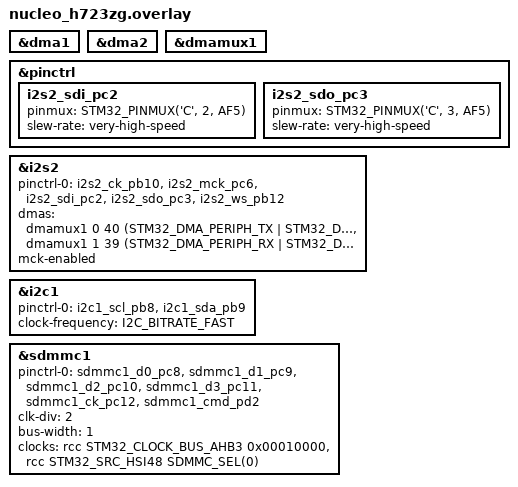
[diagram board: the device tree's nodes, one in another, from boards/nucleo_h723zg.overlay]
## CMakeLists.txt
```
# SPDX-License-Identifier: Apache-2.0

cmake_minimum_required(VERSION 3.20.0)

# Locate Zephyr and Project sources
find_package(Zephyr REQUIRED HINTS $ENV{ZEPHYR_BASE})

project(NucleoI2S)
FILE(GLOB app_sources src/*.c)
target_sources(app PRIVATE ${app_sources})
```

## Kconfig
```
menu "Zephyr"
source "Kconfig.zephyr"
endmenu

config DT_DEFINED_NOCACHE
	  bool "Enable this if nocache regions are defined in devicetree"

config DT_DEFINED_NOCACHE_NAME
	  string "Name of the nocache region defined in devicetree (capitals)"
```

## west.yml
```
# Copyright (c) 2021 Nordic Semiconductor ASA
# SPDX-License-Identifier: Apache-2.0

manifest:
  remotes:
    - name: zephyrproject-rtos-frf
      url-base: https://gitlab.firstrf.com/embedded/zephyr-demo/
    - name: zephyrproject-rtos
      url-base: https://github.com/zephyrproject-rtos

  projects:
    - name: zephyr
      remote: zephyrproject-rtos-frf
      revision: v3.6.0_frf-fixes
      import:
        # path-prefix: dep
        # By using name-allowlist we can clone only the modules that are
        # strictly needed by the application.
        name-allowlist:
          - cmsis      # required by the ARM port
          - hal_stm32  # required by stm32
          - mbedtls    # required for networking
          - littlefs   # required for settings storage
    - name: mcuboot
      remote: zephyrproject-rtos
      revision: a4eda30f5b0cfd0cf15512be9dcd559239dbfc91
      path: bootloader/mcuboot
    - name: net-tools
      remote: zephyrproject-rtos
      revision: 3a677d355cc7f73e444801a6280d0ccec80a1957
      path: tools/net-tools
    - name: zcbor
      remote: zephyrproject-rtos
      revision: d3093b5684f62268c7f27f8a5079f166772619de
      path: modules/lib/zcbor
```

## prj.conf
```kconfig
# Shell and loggings
CONFIG_SHELL=y
CONFIG_SHELL_HISTORY=y
CONFIG_SHELL_CMD_BUFF_SIZE=128
CONFIG_SHELL_STACK_SIZE=2048
CONFIG_LOG=y
CONFIG_PRINTK=y
CONFIG_MAIN_STACK_SIZE=10000

# I2S
CONFIG_I2S=y
CONFIG_I2S_STM32=y
CONFIG_HEAP_MEM_POOL_SIZE=81920

# I2C
CONFIG_I2C=y

# GPIO
CONFIG_GPIO=y
CONFIG_PINCTRL=y

# DMA
CONFIG_DMA=y

# SDMMC
CONFIG_FILE_SYSTEM=y
CONFIG_DISK_ACCESS=y
CONFIG_DISK_DRIVER_SDMMC=y
CONFIG_FAT_FILESYSTEM_ELM=y
CONFIG_SDMMC_STM32=y
CONFIG_SDMMC_STM32_CLOCK_CHECK=n
```

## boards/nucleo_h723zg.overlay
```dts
// this file overwrites zephyr/boards/st/nucleo_h723zg
// see that folder for complete board example

&dma1 {
    status = "okay";
};
&dma2 {
    status = "okay";
};
&dmamux1 {
    status = "okay";
};

&pinctrl {
    /omit-if-no-ref/ i2s2_sdi_pc2: i2s2_sdi_pc2 {
        pinmux = <STM32_PINMUX('C', 2, AF5)>;
        slew-rate = "very-high-speed";
    };

    /omit-if-no-ref/ i2s2_sdo_pc3: i2s2_sdo_pc3 {
        pinmux = <STM32_PINMUX('C', 3, AF5)>;
        slew-rate = "very-high-speed";
    };
};

&i2s2 {
    status = "okay";
    pinctrl-0 = <&i2s2_ck_pb10 &i2s2_mck_pc6 &i2s2_sdi_pc2 &i2s2_sdo_pc3 &i2s2_ws_pb12>;
    pinctrl-names = "default";
    dmas = <&dmamux1 0 40 (STM32_DMA_PERIPH_TX | STM32_DMA_PRIORITY_HIGH)
    &dmamux1 1 39 (STM32_DMA_PERIPH_RX | STM32_DMA_PRIORITY_HIGH)>;
    dma-names = "tx", "rx";
    mck-enabled;
};

&i2c1 {
    pinctrl-0 = <&i2c1_scl_pb8 &i2c1_sda_pb9>;
    pinctrl-names = "default";
    status = "okay";
    clock-frequency = <I2C_BITRATE_FAST>;
};

&sdmmc1 {
    status = "okay";
    pinctrl-0 = <
        &sdmmc1_d0_pc8
        &sdmmc1_d1_pc9
        &sdmmc1_d2_pc10
        &sdmmc1_d3_pc11
        &sdmmc1_ck_pc12
        &sdmmc1_cmd_pd2>;
    clk-div = <2>;
    bus-width = <1>;
    pinctrl-names = "default";
    clocks = <&rcc STM32_CLOCK_BUS_AHB3 0x00010000>,
        <&rcc STM32_SRC_HSI48 SDMMC_SEL(0)>;
};
```

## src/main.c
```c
#include <zephyr/kernel.h>
#include <zephyr/sys/printk.h>
#include <zephyr/drivers/i2s.h>
#include <zephyr/shell/shell.h>
#include <zephyr/drivers/i2c.h>
#include <math.h>
#include <string.h>
#include "wav_reader.h"

/* ----- definitions ----- */
#ifndef M_PI
#define M_PI 3.14159265358979323846
#endif

#define AIC3120_I2C_ADDR                                                                           \
	0x18 // Replace with your actual I2C address
	     //
#define SAMPLE_FREQUENCY   44100
#define SINE_FREQ          440   // Frequency of the sine wave (440 Hz, A4)
#define AMPLITUDE          32767 // Amplitude for 16-bit audio (max value)
#define SAMPLE_BIT_WIDTH   (16U)
#define BYTES_PER_SAMPLE   sizeof(int16_t)
#define NUMBER_OF_CHANNELS (2U)

/* Such block length provides an echo with the delay of 100 ms. */
#define SAMPLES_PER_BLOCK ((SAMPLE_FREQUENCY / 40) * NUMBER_OF_CHANNELS)
#define INITIAL_BLOCKS    2
#define TIMEOUT           (2000U)

#define BLOCK_SIZE  (BYTES_PER_SAMPLE * SAMPLES_PER_BLOCK)
#define BLOCK_COUNT (INITIAL_BLOCKS + 25)
K_MEM_SLAB_DEFINE_STATIC(mem_slab, BLOCK_SIZE, BLOCK_COUNT, 4);

/* ----- private static variables ----- */
static const struct device *dev_i2s;
static struct i2s_config i2s_cfg;
static bool stream_started = false;

static K_THREAD_STACK_DEFINE(tone_thread_stack, 4096); // Adjust stack size as needed
static struct k_thread tone_thread_data;

/* ----- private function declarations ----- */
void aic3120Init();
static bool configure_tx_streams(const struct device *dev_i2s, struct i2s_config *config);
static bool trigger_command(const struct device *dev_i2s, enum i2s_trigger_cmd cmd);

/* ----- function definitions ----- */
static void generate_sine_wave(int16_t *buffer, size_t samples_per_block, int sample_rate,
			       int frequency, int channels)
{
	static float phase = 0.0f;
	float phase_increment = 2.0f * M_PI * frequency / sample_rate;

	for (size_t i = 0; i < samples_per_block / channels; i++) {
		int16_t sample_value = (int16_t)(AMPLITUDE * sinf(phase));

		for (int ch = 0; ch < channels; ch++) {
			buffer[i * channels + ch] = sample_value;
		}

		phase += phase_increment;
		if (phase >= 2.0f * M_PI) {
			phase -= 2.0f * M_PI;
		}
	}
}

static bool configure_tx_streams(const struct device *dev_i2s, struct i2s_config *config)
{
	int ret;

	ret = i2s_configure(dev_i2s, I2S_DIR_TX, config);
	if (ret < 0) {
		printf("Failed to configure I2S stream\n");
		return false;
	}

	return true;
}

static bool trigger_command(const struct device *dev_i2s, enum i2s_trigger_cmd cmd)
{
	int ret;

	ret = i2s_trigger(dev_i2s, I2S_DIR_TX, cmd);
	if (ret < 0) {
		printk("Failed to trigger command %d on TX: %d\n", cmd, ret);
		return false;
	}

	return true;
}

#define PRE_FILL_BUFFERS 3 // Number of buffers to pre-fill before starting

void tone_thread(void *arg1, void *arg2, void *arg3)
{
	struct shell *shell = (struct shell *)arg1; // Pass shell pointer to thread
	int ret;

	bool trigger_stream = true;
	uint8_t buffer[BLOCK_SIZE]; // Buffer for file data
	uint32_t bytes_read;

	int pre_filled_buffers = 0;

	// Pre-fill multiple buffers before starting the I2S stream
	while (pre_filled_buffers < PRE_FILL_BUFFERS && stream_started) {
		void *mem_block;
		int16_t *buffer;
		uint32_t block_size = BLOCK_SIZE;

		ret = k_mem_slab_alloc(&mem_slab, &mem_block, K_FOREVER);
		if (ret < 0) {
			shell_print(shell, "Failed to allocate TX block");
			break;
		}

		buffer = (int16_t *)mem_block;
		int32_t num_read = read_data(buffer, block_size);
		if (num_read < 0) {
			shell_print(shell, "Reached end of file or error while reading data");
			k_mem_slab_free(&mem_slab, &mem_block);
			break;
		}

		ret = i2s_write(dev_i2s, mem_block, block_size);
		if (ret < 0) {
			shell_print(shell, "Failed to write data: %d", ret);
			k_mem_slab_free(&mem_slab, &mem_block);
			break;
		}

		pre_filled_buffers++;
	}

	while (stream_started) {
		void *mem_block;
		int16_t *buffer;
		uint32_t block_size = BLOCK_SIZE;

		ret = k_mem_slab_alloc(&mem_slab, &mem_block, K_FOREVER);
		if (ret < 0) {
			shell_print(shell, "Failed to allocate TX block");
			break;
		}

		buffer = (int16_t *)mem_block;
		int32_t num_read = read_data(buffer, block_size);

		ret = i2s_write(dev_i2s, mem_block, block_size);
		if (ret < 0) {
			shell_print(shell, "Failed to write data: %d", ret);
			break;
		}

		if (trigger_stream) {
			ret = i2s_trigger(dev_i2s, I2S_DIR_TX, I2S_TRIGGER_START);
			if (ret < 0) {
				shell_print(shell, "Failed to start I2S stream: %d", ret);
				break;
			}
			trigger_stream =
				false; // Set false only after stream is triggered successfully
		}

		// Add a short sleep to yield control back to the OS
	}

	if (!trigger_command(dev_i2s, I2S_TRIGGER_DROP)) {
		printk("Send I2S trigger DRAIN failed: %d", ret);
		return 0;
	}
	shell_print(shell, "thread closing down");
}

static int cmd_start_tone(const struct shell *shell, size_t argc, char **argv)
{
	if (stream_started) {
		shell_print(shell, "Tone already started");
		return 0;
	}

	shell_print(shell, "Starting tone...");
	stream_started = true;

	// Create a new thread to handle tone generation
	k_thread_create(&tone_thread_data, tone_thread_stack,
			K_THREAD_STACK_SIZEOF(tone_thread_stack), tone_thread, (void *)shell, NULL,
			NULL, 0, 0, K_NO_WAIT);

	return 0;
}

// Add a command to stop the tone generation
static int cmd_stop_tone(const struct shell *shell, size_t argc, char **argv)
{
	if (!stream_started) {
		shell_print(shell, "Tone not started");
		return 0;
	}

	shell_print(shell, "Stopping tone...");
	stream_started = false; // Signal the thread to stop

	// You may need to handle joining the thread or cleanup if necessary

	return 0;
}

/* Shell command definitions */
SHELL_CMD_ARG_REGISTER(start_tone, NULL, "Start sine wave tone", cmd_start_tone, 1, 0);
SHELL_CMD_ARG_REGISTER(stop_tone, NULL, "Stop sine wave tone", cmd_stop_tone, 1, 0);

void main(void)
{
	lsdir();
	const char *fp = "lambadio.wav";
	read_wav_file(fp);
	dev_i2s = DEVICE_DT_GET(DT_NODELABEL(i2s2));

	if (!device_is_ready(dev_i2s)) {
		printk("I2S device not ready\n");
		return;
	}

	aic3120Init();          // Initialize the codec
	stream_started = false; // Ensure the stream is initially stopped

	i2s_cfg.word_size = 16U;
	i2s_cfg.channels = 2U;
	i2s_cfg.format = I2S_FMT_DATA_FORMAT_I2S;
	i2s_cfg.frame_clk_freq = SAMPLE_FREQUENCY;
	i2s_cfg.block_size = BLOCK_SIZE;
	i2s_cfg.timeout = SYS_FOREVER_MS;
	i2s_cfg.options = I2S_OPT_FRAME_CLK_MASTER | I2S_OPT_BIT_CLK_MASTER;
	i2s_cfg.mem_slab = &mem_slab;

	if (!configure_tx_streams(dev_i2s, &i2s_cfg)) {
		printk("Failed to configure I2S stream\n");
	}

	k_msleep(1000); // Delay before starting

	printk("Shell initialized. Use 'start_tone' to start the tone and 'stop_tone' to stop "
	       "it.\n");
}

static int i2c_writeRegisterByte(const struct device *i2c_dev, uint8_t reg, uint8_t value)
{
	uint8_t data[2] = {reg, value};
	int ret = i2c_write(i2c_dev, data, sizeof(data), AIC3120_I2C_ADDR);

	// Error handling
	if (ret < 0) {
		printk("Failed to write to register 0x%02X: %d\n", reg, ret);
		return ret; // Return the error code
	}

	// printk("Wrote to register 0x%02X: 0x%02X\n", reg, value); // Log successful writes
	return 0; // Return success
}

void aic3120Init()
{
	// Initialize I2C device
	const struct device *i2c_dev;
	i2c_dev = DEVICE_DT_GET(DT_NODELABEL(i2c1));
	if (!i2c_dev) {
		printk("Failed to get I2C device");
		return;
	}

	// 1. Define starting point:
	i2c_writeRegisterByte(i2c_dev, 0, 0x00); // Set register page to 0
	i2c_writeRegisterByte(i2c_dev, 1, 0x01); // Initiate SW reset

	// 2. Program clock settings
	i2c_writeRegisterByte(i2c_dev, 4, 0x03);  // PLL_clkin = MCLK
	i2c_writeRegisterByte(i2c_dev, 6, 0x08);  // J = 8
	i2c_writeRegisterByte(i2c_dev, 7, 0x00);  // D = 0000
	i2c_writeRegisterByte(i2c_dev, 8, 0x00);  // D(7:0) = 0
	i2c_writeRegisterByte(i2c_dev, 5, 0x91);  // Power up PLL, P=1, R=1
						  //
	i2c_writeRegisterByte(i2c_dev, 11, 0x88); // Program and power up NDAC
	i2c_writeRegisterByte(i2c_dev, 12, 0x82); // Program and power up MDAC
	i2c_writeRegisterByte(i2c_dev, 13, 0x00); // DOSR = 128
	i2c_writeRegisterByte(i2c_dev, 14, 0x80); // DOSR(7:0) = 128
	i2c_writeRegisterByte(i2c_dev, 27, 0x00); // Program I2S word length and master mode
	i2c_writeRegisterByte(i2c_dev, 60, 0x10); // Select DAC DSP Processing Block PRB_P16
	i2c_writeRegisterByte(i2c_dev, 0, 0x08);
	i2c_writeRegisterByte(i2c_dev, 1, 0x04);
	i2c_writeRegisterByte(i2c_dev, 0, 0x80);

	// 3. Program analog blocks
	i2c_writeRegisterByte(i2c_dev, 0, 0x01);  // Set register page to 1
	i2c_writeRegisterByte(i2c_dev, 31, 0x04); // Program common-mode voltage
	i2c_writeRegisterByte(i2c_dev, 33, 0x4e); // Program headphone-specific depop settings
	i2c_writeRegisterByte(i2c_dev, 35, 0x40); // Route DAC output to HPOUT
	i2c_writeRegisterByte(i2c_dev, 40, 0x06); // Unmute HPOUT, set gain = 0 dB
	i2c_writeRegisterByte(i2c_dev, 42, 0x1c); // Unmute Class-D, set gain = 18 dB
	i2c_writeRegisterByte(i2c_dev, 31, 0x82); // HPOUT powered up
	i2c_writeRegisterByte(i2c_dev, 32, 0xc6); // Power-up Class-D drivers
	i2c_writeRegisterByte(i2c_dev, 36, 0x92); // Set HPOUT output analog volume
	i2c_writeRegisterByte(i2c_dev, 38, 0x92); // Set Class-D output analog volume

	// 5. Power up DAC
	i2c_writeRegisterByte(i2c_dev, 0, 0x00);  // Power up DAC
	i2c_writeRegisterByte(i2c_dev, 63, 0x94); // Power up DAC channels and set digital gain
	i2c_writeRegisterByte(i2c_dev, 65, 0xd4); // DAC gain = -22 dB
	i2c_writeRegisterByte(i2c_dev, 64, 0x04); // Unmute DAC
}
```

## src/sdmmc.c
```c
/*
 * Copyright (c) 2019 Tavish Naruka <tavishnaruka@gmail.com>
 * Copyright (c) 2023 Nordic Semiconductor ASA
 * Copyright (c) 2023 Antmicro <www.antmicro.com>
 *
 * SPDX-License-Identifier: Apache-2.0
 */

/* Sample which uses the filesystem API and SDHC driver */
#include <stdio.h>
#include <stdlib.h>
#include <string.h>

#include <zephyr/kernel.h>
#include <zephyr/device.h>
#include <zephyr/storage/disk_access.h>
#include <zephyr/logging/log.h>
#include <zephyr/fs/fs.h>
#include <zephyr/shell/shell.h>
#include <zephyr/drivers/i2c.h>

#if defined(CONFIG_FAT_FILESYSTEM_ELM)

#include <ff.h>

/*
 *  Note the fatfs library is able to mount only strings inside _VOLUME_STRS
 *  in ffconf.h
 */
#define DISK_DRIVE_NAME "SD"
#define DISK_MOUNT_PT   "/" DISK_DRIVE_NAME ":"

static FATFS fat_fs;
/* mounting info */
static struct fs_mount_t mp = {
	.type = FS_FATFS,
	.fs_data = &fat_fs,
};

#elif defined(CONFIG_FILE_SYSTEM_EXT2)

#include <zephyr/fs/ext2.h>

#define DISK_DRIVE_NAME "SDMMC"
#define DISK_MOUNT_PT   "/ext"

static struct fs_mount_t mp = {
	.type = FS_EXT2,
	.flags = FS_MOUNT_FLAG_NO_FORMAT,
	.storage_dev = (void *)DISK_DRIVE_NAME,
	.mnt_point = "/ext",
};

#endif

#if defined(CONFIG_FAT_FILESYSTEM_ELM)
#define FS_RET_OK FR_OK
#else
#define FS_RET_OK 0
#endif

LOG_MODULE_REGISTER(main);

#define MAX_PATH          128
#define SOME_FILE_NAME    "some.dat"
#define SOME_DIR_NAME     "some"
#define SOME_REQUIRED_LEN MAX(sizeof(SOME_FILE_NAME), sizeof(SOME_DIR_NAME))

static int lsdir(const char *path);
static int cmd_g_fs_read(const struct shell *shell, size_t argc, char *argv[]);
void aic3120Init();
#ifdef CONFIG_FS_SAMPLE_CREATE_SOME_ENTRIES
static bool create_some_entries(const char *base_path)
{
	char path[MAX_PATH];
	struct fs_file_t file;
	int base = strlen(base_path);

	fs_file_t_init(&file);

	if (base >= (sizeof(path) - SOME_REQUIRED_LEN)) {
		LOG_ERR("Not enough concatenation buffer to create file paths");
		return false;
	}

	LOG_INF("Creating some dir entries in %s", base_path);
	strncpy(path, base_path, sizeof(path));

	path[base++] = '/';
	path[base] = 0;
	strcat(&path[base], SOME_FILE_NAME);

	if (fs_open(&file, path, FS_O_CREATE) != 0) {
		LOG_ERR("Failed to create file %s", path);
		return false;
	}
	fs_close(&file);

	path[base] = 0;
	strcat(&path[base], SOME_DIR_NAME);

	if (fs_mkdir(path) != 0) {
		LOG_ERR("Failed to create dir %s", path);
		/* If code gets here, it has at least successes to create the
		 * file so allow function to return true.
		 */
	}
	return true;
}
#endif

static const char *disk_mount_pt = DISK_MOUNT_PT;

int main(void)
{
	aic3120Init();
	/* Create shell cmds for fs */
	SHELL_STATIC_SUBCMD_SET_CREATE(g_fs_cmds,
				       SHELL_CMD_ARG(read, NULL,
						     "Read contents from a file\n"
						     "usage:\n"
						     "$ fs read <FNAME>\n"
						     "example:\n"
						     "$ fs read test.txt\n",
						     cmd_g_fs_read, 2, 0),
				       SHELL_SUBCMD_SET_END);
	SHELL_CMD_REGISTER(fs, &g_fs_cmds, "Access the SD FAT filesystem", NULL);

	/* raw disk i/o */
	do {
		static const char *disk_pdrv = DISK_DRIVE_NAME;
		uint64_t memory_size_mb;
		uint32_t block_count;
		uint32_t block_size;

		if (disk_access_ioctl(disk_pdrv, DISK_IOCTL_CTRL_INIT, NULL) != 0) {
			LOG_ERR("Storage init ERROR!");
			break;
		}

		if (disk_access_ioctl(disk_pdrv, DISK_IOCTL_GET_SECTOR_COUNT, &block_count)) {
			LOG_ERR("Unable to get sector count");
			break;
		}
		LOG_INF("Block count %u", block_count);

		if (disk_access_ioctl(disk_pdrv, DISK_IOCTL_GET_SECTOR_SIZE, &block_size)) {
			LOG_ERR("Unable to get sector size");
			break;
		}
		printk("Sector size %u\n", block_size);

		memory_size_mb = (uint64_t)block_count * block_size;
		printk("Memory Size(MB) %u\n", (uint32_t)(memory_size_mb >> 20));

		if (disk_access_ioctl(disk_pdrv, DISK_IOCTL_CTRL_DEINIT, NULL) != 0) {
			LOG_ERR("Storage deinit ERROR!");
			break;
		}
	} while (0);

	mp.mnt_point = disk_mount_pt;

	int res = fs_mount(&mp);

	if (res == FS_RET_OK) {
		printk("Disk mounted.\n");
		/* Try to unmount and remount the disk */
		res = fs_unmount(&mp);
		if (res != FS_RET_OK) {
			printk("Error unmounting disk\n");
			return res;
		}
		res = fs_mount(&mp);
		if (res != FS_RET_OK) {
			printk("Error remounting disk\n");
			return res;
		}

		if (lsdir(disk_mount_pt) == 0) {
#ifdef CONFIG_FS_SAMPLE_CREATE_SOME_ENTRIES
			if (create_some_entries(disk_mount_pt)) {
				lsdir(disk_mount_pt);
			}
#endif
		}
	} else {
		printk("Error mounting disk.\n");
	}

	fs_unmount(&mp);

	while (1) {
		k_sleep(K_MSEC(1000));
	}

	return 0;
}

/* List dir entry by path
 *
 * @param path Absolute path to list
 *
 * @return Negative errno code on error, number of listed entries on
 *         success.
 */
static int lsdir(const char *path)
{
	int res;
	struct fs_dir_t dirp;
	static struct fs_dirent entry;
	int count = 0;

	fs_dir_t_init(&dirp);

	/* Verify fs_opendir() */
	res = fs_opendir(&dirp, path);
	if (res) {
		printk("Error opening dir %s [%d]\n", path, res);
		return res;
	}

	printk("\nListing dir %s ...\n", path);
	for (;;) {
		/* Verify fs_readdir() */
		res = fs_readdir(&dirp, &entry);

		/* entry.name[0] == 0 means end-of-dir */
		if (res || entry.name[0] == 0) {
			break;
		}

		if (entry.type == FS_DIR_ENTRY_DIR) {
			printk("[DIR ] %s\n", entry.name);
		} else {
			printk("[FILE] %s (size = %zu)\n", entry.name, entry.size);
		}
		count++;
	}

	/* Verify fs_closedir() */
	fs_closedir(&dirp);
	if (res == 0) {
		res = count;
	}

	return res;
}

static int cmd_g_fs_read(const struct shell *shell, size_t argc, char *argv[])
{
	int rc;
	struct fs_dirent dirent;
	struct fs_file_t file;
	int res;

	/* Combine the mount point and fname for a full path */
	const char *separator = "/";
	size_t newSize = strlen(mp.mnt_point) + strlen(separator) + strlen(argv[1]) + 1;
	char *fpath = malloc(newSize);
	if (fpath == NULL) {
		shell_fprintf(shell, SHELL_ERROR,
			      "FAIL: could not combine mount point (%s) with fname (%s)",
			      mp.mnt_point, argv[1]);
		return 1;
	}
	strcpy(fpath, mp.mnt_point);
	strcat(fpath, separator);
	strcat(fpath, argv[1]);
	shell_fprintf(shell, SHELL_NORMAL, "full filepath=%s\n", fpath);

	/* Mount the filesystem */
	res = fs_mount(&mp);
	if (res != FS_RET_OK) {
		printk("Error remounting disk\n");
		free(fpath);
		return res;
	}

	/* Open the file */
	fs_file_t_init(&file);
	rc = fs_open(&file, fpath, FS_O_READ);
	if (rc < 0) {
		shell_fprintf(shell, SHELL_ERROR, "FAIL: open %s: %d", fpath, rc);
		free(fpath);
		return rc;
	}

	/* Get file length */
	rc = fs_stat(fpath, &dirent);
	if (rc < 0) {
		shell_fprintf(shell, SHELL_ERROR, "FAIL: could not get filesize");
		free(fpath);
		fs_close(&file); // Close file if opened
		return rc;
	}
	shell_fprintf(shell, SHELL_NORMAL, "Filesize = %d\n", dirent.size);

	/* Allocate a byte array of the size of the file */
	size_t file_size = dirent.size;
	uint8_t *byte_array = malloc(file_size);
	if (byte_array == NULL) {
		shell_fprintf(shell, SHELL_ERROR,
			      "FAIL: could not allocate memory for file contents");
		free(fpath);
		fs_close(&file); // Close file if opened
		return 1;
	}

	/* Read the file into the byte array */
	rc = fs_read(&file, byte_array, file_size);
	if (rc < 0) {
		shell_fprintf(shell, SHELL_ERROR, "FAIL: read %s: [rd:%d]", fpath, rc);
		free(byte_array);
		free(fpath);
		fs_close(&file); // Close file if opened
		return rc;
	}

	shell_fprintf(shell, SHELL_NORMAL, "Read %d bytes from file.\n", rc);

	// Assuming you want to print the byte array as a string, ensure null termination
	if (file_size < UINT8_MAX) {
		byte_array[file_size] = '\0'; // Null-terminate for string display
	}

	shell_fprintf(shell, SHELL_NORMAL, "contents:\n%s\n", (char *)byte_array);

	/* Clean up */
	free(byte_array);
	fs_close(&file); // Close the file after reading
	fs_unmount(&mp);
	free(fpath);

	return 0;
}

#define AIC3120_I2C_ADDR 0x18 // Replace with your actual I2C address

static const struct device *i2c_dev;

static int i2c_writeRegisterByte(uint8_t reg, uint8_t value)
{
	uint8_t data[2] = {reg, value};
	int ret = i2c_write(i2c_dev, data, sizeof(data), AIC3120_I2C_ADDR);

	// Error handling
	if (ret < 0) {
		LOG_ERR("Failed to write to register 0x%02X: %d", reg, ret);
		return ret; // Return the error code
	}

	LOG_INF("Wrote to register 0x%02X: 0x%02X", reg, value); // Log successful writes
	return 0;                                                // Return success
}

void aic3120Init()
{
	// Initialize I2C device
	i2c_dev = DEVICE_DT_GET(DT_NODELABEL(i2c1));
	if (!i2c_dev) {
		LOG_ERR("Failed to get I2C device");
		return;
	}

	// 1. Define starting point:
	i2c_writeRegisterByte(0, 0x00); // Set register page to 0
	i2c_writeRegisterByte(1, 0x01); // Initiate SW reset

	// 2. Program clock settings
	i2c_writeRegisterByte(4, 0x03);  // PLL_clkin = MCLK
	i2c_writeRegisterByte(6, 0x08);  // J = 8
	i2c_writeRegisterByte(7, 0x00);  // D = 0000
	i2c_writeRegisterByte(8, 0x00);  // D(7:0) = 0
	i2c_writeRegisterByte(5, 0x91);  // Power up PLL
	i2c_writeRegisterByte(11, 0x88); // Program and power up NDAC
	i2c_writeRegisterByte(12, 0x82); // Program and power up MDAC
	i2c_writeRegisterByte(13, 0x00); // DOSR = 128
	i2c_writeRegisterByte(14, 0x80); // DOSR(7:0) = 128
	i2c_writeRegisterByte(27, 0x00); // Program I2S word length and master mode
	i2c_writeRegisterByte(60, 0x10); // Select DAC DSP Processing Block PRB_P16
	i2c_writeRegisterByte(0, 0x08);
	i2c_writeRegisterByte(1, 0x04);
	i2c_writeRegisterByte(0, 0x80);

	// 3. Program analog blocks
	i2c_writeRegisterByte(0, 0x01);  // Set register page to 1
	i2c_writeRegisterByte(31, 0x04); // Program common-mode voltage
	i2c_writeRegisterByte(33, 0x4e); // Program headphone-specific depop settings
	i2c_writeRegisterByte(35, 0x40); // Route DAC output to HPOUT
	i2c_writeRegisterByte(40, 0x06); // Unmute HPOUT, set gain = 0 dB
	i2c_writeRegisterByte(42, 0x1c); // Unmute Class-D, set gain = 18 dB
	i2c_writeRegisterByte(31, 0x82); // HPOUT powered up
	i2c_writeRegisterByte(32, 0xc6); // Power-up Class-D drivers
	i2c_writeRegisterByte(36, 0x92); // Set HPOUT output analog volume
	i2c_writeRegisterByte(38, 0x92); // Set Class-D output analog volume

	// 5. Power up DAC
	i2c_writeRegisterByte(0, 0x00);  // Power up DAC
	i2c_writeRegisterByte(63, 0x94); // Power up DAC channels and set digital gain
	i2c_writeRegisterByte(65, 0xd4); // DAC gain = -22 dB
	i2c_writeRegisterByte(64, 0x04); // Unmute DAC
}
```

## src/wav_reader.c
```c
#include <stdio.h>
#include <stdlib.h>
#include <string.h>

#include <zephyr/kernel.h>
#include <zephyr/device.h>
#include <zephyr/storage/disk_access.h>
#include <zephyr/logging/log.h>
#include <zephyr/fs/fs.h>
#include <zephyr/shell/shell.h>
#include <zephyr/drivers/i2c.h>

#include <ff.h>
#include "wav_reader.h"

/* ----- module registers ----- */
LOG_MODULE_REGISTER(wav_reader, LOG_LEVEL_INF);

/* ----- definitions ----- */

/*
 *  Note the fatfs library is able to mount only strings inside _VOLUME_STRS
 *  in ffconf.h
 */
#define DISK_DRIVE_NAME "SD"
#define DISK_MOUNT_PT   "/" DISK_DRIVE_NAME ":"
#define FS_RET_OK       FR_OK

#define MAX_PATH          128
#define SOME_FILE_NAME    "some.dat"
#define SOME_DIR_NAME     "some"
#define SOME_REQUIRED_LEN MAX(sizeof(SOME_FILE_NAME), sizeof(SOME_DIR_NAME))

/* ----- private static variables and types ----- */
static FATFS fat_fs;
static FIL wav_file;
static FILINFO fno;
static FRESULT res;

/* mounting info */
static struct fs_mount_t mp = {
	.type = FS_FATFS,
	.fs_data = &fat_fs,
};
static const char *disk_mount_pt = DISK_MOUNT_PT;

/* ----- private function declarations ----- */

/* ----- function definitions ----- */
void read_wav_file(const char *file_name)
{
	WavHeader wav_header;
	UINT bytes_read;

	// Mount the filesystem
	mp.mnt_point = disk_mount_pt;
	res = fs_mount(&mp);
	if (res != FR_OK) {
		LOG_ERR("Failed to mount filesystem: %d", res);
		return;
	}

	/* Combine the mount point and fname for a full path */
	const char *separator = "/";
	size_t newSize = strlen(mp.mnt_point) + strlen(separator) + strlen(file_name) + 1;
	char *fpath = malloc(newSize);
	if (fpath == NULL) {
		LOG_ERR("FAIL: could not combine mount point (%s) with fname (%s)", mp.mnt_point,
			file_name);
	}
	strcpy(fpath, mp.mnt_point);
	strcat(fpath, separator);
	strcat(fpath, file_name);

	// Open the WAV file
	res = fs_open(&wav_file, fpath, FS_O_READ);
	if (res != FR_OK) {
		LOG_ERR("Failed to open file: %d", res);
		free(fpath);
		return;
	}

	// Read the WAV file header
	res = fs_read(&wav_file, &wav_header, sizeof(WavHeader));
	if (res < 0) {
		LOG_ERR("Failed to read WAV header: %d", res);
		fs_close(&wav_file);
		free(fpath);
		return;
	}

	// Check if it's a valid WAV file
	if (strncmp(wav_header.chunk_id, "RIFF", 4) != 0 ||
	    strncmp(wav_header.format, "WAVE", 4) != 0) {
		LOG_ERR("Invalid WAV file format");
		fs_close(&wav_file);
		free(fpath);
		return;
	}

	LOG_INF("WAV File Info:");
	LOG_INF("  Sample Rate: %u Hz", wav_header.sample_rate);
	LOG_INF("  Channels: %u", wav_header.num_channels);
	LOG_INF("  Bits per Sample: %u", wav_header.bits_per_sample);

	// Read WAV data (subchunk2) here, process the audio samples as needed

	// If the subchunk2 is not DATA, then read past this chunk
	uint8_t buffer[512]; // Adjust size based on your needs
	if (strncmp(wav_header.subchunk2_id, "DATA", 4) != 0) {
		int32_t subchunk2_sz = wav_header.subchunk2_size;

		// Keep reading until we reach the end
		while (subchunk2_sz > 0) {
			int rd_sz = (subchunk2_sz < sizeof(buffer)) ? subchunk2_sz : sizeof(buffer);
			res = fs_read(&wav_file, buffer, rd_sz);
			if (res < 0) {
				LOG_ERR("Failed to skip past subchunk2");
				fs_close(&wav_file);
				free(fpath);
				return;
			}
			subchunk2_sz -= res;
		}
	}

	// Should be on the DATA subchunk now
	SubchunkHeader subchunk_header;
	res = fs_read(&wav_file, &subchunk_header, sizeof(subchunk_header));
	if (res < 0) {
		LOG_ERR("Error reading WAV data: %d", res);
		free(fpath);
	}

	// Free the unused path
	free(fpath);
}

int32_t read_data(int16_t *buffer, uint32_t block_size)
{
	res = fs_read(&wav_file, buffer, block_size);
	return res;
}

/* List dir entry by path
 *
 * @param path Absolute path to list
 *
 * @return Negative errno code on error, number of listed entries on
 *         success.
 */
void lsdir(void)
{
	const char *path = disk_mount_pt;
	struct fs_dir_t dirp;
	static struct fs_dirent entry;
	int count = 0;

	// Mount the filesystem
	mp.mnt_point = disk_mount_pt;
	res = fs_mount(&mp);
	if (res != FR_OK) {
		LOG_ERR("Failed to mount filesystem: %d", res);
		return;
	}

	fs_dir_t_init(&dirp);

	/* Verify fs_opendir() */
	res = fs_opendir(&dirp, path);
	if (res) {
		printk("Error opening dir %s [%d]\n", path, res);
		return;
	}

	printk("\nListing dir %s ...\n", path);
	for (;;) {
		/* Verify fs_readdir() */
		res = fs_readdir(&dirp, &entry);

		/* entry.name[0] == 0 means end-of-dir */
		if (res || entry.name[0] == 0) {
			break;
		}

		if (entry.type == FS_DIR_ENTRY_DIR) {
			printk("[DIR ] %s\n", entry.name);
		} else {
			printk("[FILE] %s (size = %zu)\n", entry.name, entry.size);
		}
		count++;
	}

	/* Verify fs_closedir() */
	fs_closedir(&dirp);
	if (res == 0) {
		res = count;
	}
	fs_unmount(&mp);

	return;
}
```

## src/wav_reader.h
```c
#ifndef WAV_READER_H_
#define WAV_READER_H_

#include <ff.h> // FatFS headers

// WAV file header structure
typedef struct {
	char chunk_id[4]; // "RIFF"
	uint32_t chunk_size;
	char format[4];       // "WAVE"
	char subchunk1_id[4]; // "fmt "
	uint32_t subchunk1_size;
	uint16_t audio_format;
	uint16_t num_channels;
	uint32_t sample_rate;
	uint32_t byte_rate;
	uint16_t block_align;
	uint16_t bits_per_sample;
	char subchunk2_id[4];
	uint32_t subchunk2_size;
} WavHeader;

typedef struct {
	char subchunk_id[4]; // "data"
	uint32_t subchunk_size;
} SubchunkHeader;

// Function to read a WAV file
void read_wav_file(const char *file_name);
int32_t read_data(int16_t *buffer, uint32_t block_size);

void lsdir(void);

#endif /* WAV_READER_H_ */
```
